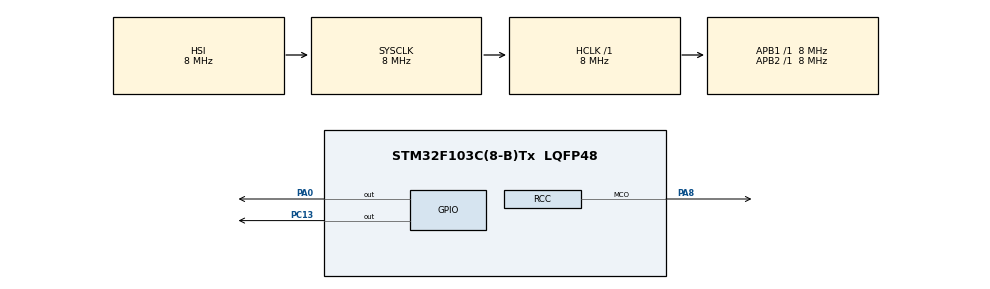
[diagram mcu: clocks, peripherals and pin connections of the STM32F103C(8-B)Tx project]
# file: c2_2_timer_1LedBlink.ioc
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Mcu.Family=STM32F1
Mcu.Name=STM32F103C(8-B)Tx
Mcu.Package=LQFP48
NVIC.PriorityGroup=NVIC_PRIORITYGROUP_4
NVIC.TIM3_IRQn=true\:0\:0\:false\:false\:true\:true\:true\:true
PA0-WKUP.Signal=GPIO_Output
PA8.Mode=Clock-out
PA8.Signal=RCC_MCO
PC13-TAMPER-RTC.Signal=GPIO_Output
ProjectManager.HeapSize=0x200
ProjectManager.StackSize=0x400
ProjectManager.TargetToolchain=STM32CubeIDE
RCC.AHBFreq_Value=8000000
RCC.APB1Freq_Value=8000000
RCC.APB1TimFreq_Value=8000000
RCC.APB2Freq_Value=8000000
RCC.APB2TimFreq_Value=8000000
RCC.HCLKFreq_Value=8000000
RCC.SYSCLKFreq_VALUE=8000000
RCC.USBFreq_Value=8000000
TIM3.Period=1000-1
TIM3.Prescaler=8-1
VP_SYS_VS_ND.Mode=No_Debug
VP_TIM3_VS_ClockSourceINT.Mode=Internal
board=custom

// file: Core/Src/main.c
/* USER CODE BEGIN Header */
/**
  ******************************************************************************
  * @file           : main.c
  * @brief          : Main program body
  ******************************************************************************
  * @attention
  *
  * Copyright (c) 2025 STMicroelectronics.
  * All rights reserved.
  *
  * This software is licensed under terms that can be found in the LICENSE file
  * in the root directory of this software component.
  * If no LICENSE file comes with this software, it is provided AS-IS.
  *
  ******************************************************************************
  */
/* USER CODE END Header */
#include "main.h"

TIM_HandleTypeDef htim3;

void SystemClock_Config(void);
static void MX_GPIO_Init(void);
static void MX_TIM3_Init(void);
/* USER CODE BEGIN PFP */
void delay(int time);
/* USER CODE END PFP */

int main(void)
{

  /* MCU Configuration--------------------------------------------------------*/

  /* Reset of all peripherals, Initializes the Flash interface and the Systick. */
  HAL_Init();

  /* Configure the system clock */
  SystemClock_Config();

  /* Initialize all configured peripherals */
  MX_GPIO_Init();
  MX_TIM3_Init();
  /* USER CODE BEGIN 2 */
  HAL_RCC_MCOConfig(RCC_MCO1, RCC_MCO1SOURCE_HSI , RCC_MCODIV_1);
  /* USER CODE END 2 */

  /* Infinite loop */
  while (1)
  {

    /* USER CODE BEGIN 3 */
	  HAL_GPIO_WritePin(GPIOC, GPIO_PIN_13, 1);
	  delay(1000);
	  HAL_GPIO_WritePin(GPIOC, GPIO_PIN_13, 0);
	  delay(1000);
  }
  /* USER CODE END 3 */
}

void SystemClock_Config(void)
{
  RCC_OscInitTypeDef RCC_OscInitStruct = {0};
  RCC_ClkInitTypeDef RCC_ClkInitStruct = {0};

  /** Initializes the RCC Oscillators according to the specified parameters
  * in the RCC_OscInitTypeDef structure.
  */
  RCC_OscInitStruct.OscillatorType = RCC_OSCILLATORTYPE_HSI;
  RCC_OscInitStruct.HSIState = RCC_HSI_ON;
  RCC_OscInitStruct.HSICalibrationValue = RCC_HSICALIBRATION_DEFAULT;
  RCC_OscInitStruct.PLL.PLLState = RCC_PLL_NONE;
  if (HAL_RCC_OscConfig(&RCC_OscInitStruct) != HAL_OK)
  {
    Error_Handler();
  }

  /** Initializes the CPU, AHB and APB buses clocks
  */
  RCC_ClkInitStruct.ClockType = RCC_CLOCKTYPE_HCLK|RCC_CLOCKTYPE_SYSCLK
                              |RCC_CLOCKTYPE_PCLK1|RCC_CLOCKTYPE_PCLK2;
  RCC_ClkInitStruct.SYSCLKSource = RCC_SYSCLKSOURCE_HSI;
  RCC_ClkInitStruct.AHBCLKDivider = RCC_SYSCLK_DIV1;
  RCC_ClkInitStruct.APB1CLKDivider = RCC_HCLK_DIV1;
  RCC_ClkInitStruct.APB2CLKDivider = RCC_HCLK_DIV1;

  if (HAL_RCC_ClockConfig(&RCC_ClkInitStruct, FLASH_LATENCY_0) != HAL_OK)
  {
    Error_Handler();
  }
  HAL_RCC_MCOConfig(RCC_MCO, RCC_MCO1SOURCE_SYSCLK, RCC_MCODIV_1);
}

static void MX_TIM3_Init(void)
{

  TIM_ClockConfigTypeDef sClockSourceConfig = {0};
  TIM_MasterConfigTypeDef sMasterConfig = {0};

  htim3.Instance = TIM3;
  htim3.Init.Prescaler = 8-1;
  htim3.Init.CounterMode = TIM_COUNTERMODE_UP;
  htim3.Init.Period = 1000-1;
  htim3.Init.ClockDivision = TIM_CLOCKDIVISION_DIV1;
  htim3.Init.AutoReloadPreload = TIM_AUTORELOAD_PRELOAD_DISABLE;
  if (HAL_TIM_Base_Init(&htim3) != HAL_OK)
  {
    Error_Handler();
  }
  sClockSourceConfig.ClockSource = TIM_CLOCKSOURCE_INTERNAL;
  if (HAL_TIM_ConfigClockSource(&htim3, &sClockSourceConfig) != HAL_OK)
  {
    Error_Handler();
  }
  sMasterConfig.MasterOutputTrigger = TIM_TRGO_RESET;
  sMasterConfig.MasterSlaveMode = TIM_MASTERSLAVEMODE_DISABLE;
  if (HAL_TIMEx_MasterConfigSynchronization(&htim3, &sMasterConfig) != HAL_OK)
  {
    Error_Handler();
  }

}

static void MX_GPIO_Init(void)
{
  GPIO_InitTypeDef GPIO_InitStruct = {0};

  /* GPIO Ports Clock Enable */
  __HAL_RCC_GPIOC_CLK_ENABLE();
  __HAL_RCC_GPIOA_CLK_ENABLE();

  /*Configure GPIO pin Output Level */
  HAL_GPIO_WritePin(GPIOC, GPIO_PIN_13, GPIO_PIN_RESET);

  /*Configure GPIO pin Output Level */
  HAL_GPIO_WritePin(GPIOA, GPIO_PIN_0, GPIO_PIN_RESET);

  /*Configure GPIO pin : PC13 */
  GPIO_InitStruct.Pin = GPIO_PIN_13;
  GPIO_InitStruct.Mode = GPIO_MODE_OUTPUT_PP;
  GPIO_InitStruct.Pull = GPIO_NOPULL;
  GPIO_InitStruct.Speed = GPIO_SPEED_FREQ_LOW;
  HAL_GPIO_Init(GPIOC, &GPIO_InitStruct);

  /*Configure GPIO pin : PA0 */
  GPIO_InitStruct.Pin = GPIO_PIN_0;
  GPIO_InitStruct.Mode = GPIO_MODE_OUTPUT_PP;
  GPIO_InitStruct.Pull = GPIO_NOPULL;
  GPIO_InitStruct.Speed = GPIO_SPEED_FREQ_LOW;
  HAL_GPIO_Init(GPIOA, &GPIO_InitStruct);

  /*Configure GPIO pin : PA8 */
  GPIO_InitStruct.Pin = GPIO_PIN_8;
  GPIO_InitStruct.Mode = GPIO_MODE_AF_PP;
  GPIO_InitStruct.Speed = GPIO_SPEED_FREQ_LOW;
  HAL_GPIO_Init(GPIOA, &GPIO_InitStruct);

}

/* USER CODE BEGIN 4 */
void delay(int time)
{
	int i=0;
    __HAL_TIM_CLEAR_FLAG(&htim3, TIM_FLAG_UPDATE); // Clear UIF
	for(i=0;i<time;i++){
    __HAL_TIM_SET_COUNTER(&htim3, 0);          // Reset counter
    HAL_TIM_Base_Start(&htim3);
    while (__HAL_TIM_GET_FLAG(&htim3, TIM_FLAG_UPDATE) == RESET)
    {
        // Polling until UIF (Update Interrupt Flag) sets
    }
// when Update Interrupt flag is 1 the code comes here
    HAL_TIM_Base_Stop(&htim3);
    __HAL_TIM_CLEAR_FLAG(&htim3, TIM_FLAG_UPDATE); // Clear flag
	}
}
/* USER CODE END 4 */

void Error_Handler(void)
{
  __disable_irq();
  while (1)
  {
  }
}
